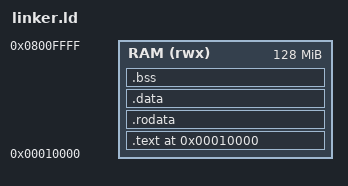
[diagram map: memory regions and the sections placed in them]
/* Linker script for RISC-V bare-metal programs */

OUTPUT_ARCH(riscv)
ENTRY(_start)

MEMORY
{
    RAM (rwx) : ORIGIN = 0x10000, LENGTH = 128M
}

SECTIONS
{
    . = ORIGIN(RAM);

    .text : {
        *(.text.init)
        *(.text .text.*)
    } > RAM

    .rodata : {
        *(.rodata .rodata.*)
    } > RAM

    .data : {
        *(.data .data.*)
        *(.sdata .sdata.*)
    } > RAM

    .bss : {
        _bss_start = .;
        *(.bss .bss.*)
        *(.sbss .sbss.*)
        *(COMMON)
        _bss_end = .;
    } > RAM

    . = ALIGN(16);
    . = . + 0x10000;  /* 64KB stack */
    _stack_top = .;

    /DISCARD/ : {
        *(.comment)
        *(.note*)
        *(.eh_frame*)
    }
}
